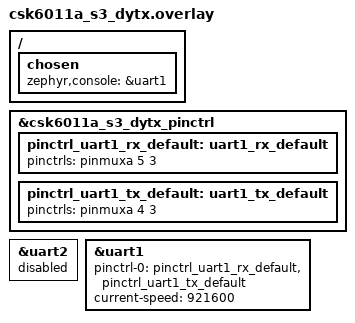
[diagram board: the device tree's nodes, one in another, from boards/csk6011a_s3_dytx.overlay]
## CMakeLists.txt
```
cmake_minimum_required(VERSION 3.20.0)

# SPDX-License-Identifier: Apache-2.0
#

set(BOARD_ROOT ${CMAKE_CURRENT_LIST_DIR})

set(ENV{XCC_USE_CLANG} "1")
set(ENV{ZEPHYR_TOOLCHAIN_VARIANT} "xcc")


find_package(Zephyr HINTS $ENV{ZEPHYR_BASE})
project(sample_sof)

target_sources(app PRIVATE
    src/main.c
  )

zephyr_ld_options(-Wl,--wrap,calloc -Wl,--wrap,malloc -Wl,--wrap,free -Wl,--wrap,printf)

zephyr_interface_library_named(sof_lib)

zephyr_library_include_directories(app PUBLIC
    ${sof_module}/src/arch/xtensa/include
    ${sof_module}/src/include
  )
```

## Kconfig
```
source "Kconfig.zephyr"

config 25M_XTAL
	bool "Use 25M XTAL instead of 24M XTAL"
	default n
	help
	  Use 25M XTAL instead of 24M XTAL
```

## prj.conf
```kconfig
CONFIG_SOF=y
CONFIG_LOG=y
CONFIG_LOG_PRINTK=y
CONFIG_LOG_MODE_MINIMAL=y

CONFIG_BUILD_OUTPUT_BIN=y
CONFIG_IPM=y
# Requires heap_info() be implemented, but no Zephyr wrapper
CONFIG_DEBUG_MEMORY_USAGE_SCAN=n

CONFIG_SCHED_DEADLINE=y
CONFIG_SCHED_CPU_MASK=y
CONFIG_SMP_BOOT_DELAY=y

#mp3 deocder
CONFIG_COMP_CODEC_ADAPTER=y
CONFIG_CADENCE_CODEC=y
CONFIG_CADENCE_CODEC_MP3_DEC=y

# cp xip
#CONFIG_CP_XIP=y
#CONFIG_CP_XIP_RUN_ADDRESS=0x68180000
#CONFIG_CP_XIP_MAX_SIZE=0x140000

# ai
#CONFIG_SOF_AI_CV=y
#CONFIG_SOF_AI_CUTLINE_RES_ADDR=0x682c0000
#CONFIG_SOF_AI_CUTLINE_RES_SIZE=0x69228
#CONFIG_SOF_AI_OCR_RES_ADDR=0x68340000
#CONFIG_SOF_AI_OCR_RES_SIZE=0x2F94A8
#CONFIG_SOF_AI_TTS_RES_ADDR=0x68640000
#CONFIG_SOF_AI_TRANS_RES_ADDR=0x68f80000

# xtensa back trace
CONFIG_XTENSA_ENABLE_BACKTRACE=y

# external libc 
# CONFIG_PRINTK=y
# CONFIG_CBPRINTF_FP_SUPPORT=y
CONFIG_STDOUT_CONSOLE=n
CONFIG_EXTERNAL_LIBC=y

# thread stack information
CONFIG_STACK_SENTINEL=y
CONFIG_INIT_STACKS=y
```

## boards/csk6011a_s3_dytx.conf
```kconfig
CONFIG_CSK6=y
CONFIG_HAVE_AGENT=n
CONFIG_FORMAT_CONVERT_HIFI3=n
CONFIG_KPB_FORCE_COPY_TYPE_NORMAL=n


# cp xip
CONFIG_CP_XIP=y
CONFIG_CP_XIP_RUN_ADDRESS=0x68180000
CONFIG_CP_XIP_MAX_SIZE=0x140000

# ai
CONFIG_SOF_AI_CV=y
CONFIG_SOF_AI_CUTLINE_RES_ADDR=0x682c0000
CONFIG_SOF_AI_CUTLINE_RES_SIZE=0x69228
CONFIG_SOF_AI_OCR_RES_ADDR=0x68340000
CONFIG_SOF_AI_OCR_RES_SIZE=0x2F94A8
CONFIG_SOF_AI_TTS_RES_ADDR=0x68640000
CONFIG_SOF_AI_TRANS_RES_ADDR=0x68f80000

CONFIG_DSP_TTS_STREAM_OUTPUT=y
```

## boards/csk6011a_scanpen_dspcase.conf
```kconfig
CONFIG_CSK6=y
CONFIG_HAVE_AGENT=n
CONFIG_FORMAT_CONVERT_HIFI3=n
CONFIG_KPB_FORCE_COPY_TYPE_NORMAL=n


# cp xip
CONFIG_CP_XIP=y
CONFIG_CP_XIP_RUN_ADDRESS=0x68460000
CONFIG_CP_XIP_MAX_SIZE=0x140000

# ai
CONFIG_SOF_AI_CV=y
CONFIG_SOF_AI_CUTLINE_RES_ADDR=0x685a0000
CONFIG_SOF_AI_CUTLINE_RES_SIZE=0x69228
CONFIG_SOF_AI_OCR_RES_ADDR=0x68620000
CONFIG_SOF_AI_OCR_RES_SIZE=0x26a0d8
CONFIG_SOF_AI_TTS_RES_ADDR=0x688a0000
CONFIG_SOF_AI_TRANS_RES_ADDR=0x68ae0000
```

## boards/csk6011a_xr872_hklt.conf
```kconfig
CONFIG_CSK6=y
CONFIG_HAVE_AGENT=n
CONFIG_FORMAT_CONVERT_HIFI3=n
CONFIG_KPB_FORCE_COPY_TYPE_NORMAL=n


# cp xip
CONFIG_CP_XIP=y
CONFIG_CP_XIP_RUN_ADDRESS=0x68100000
CONFIG_CP_XIP_MAX_SIZE=0x1b0000

# ai
CONFIG_SOF_AI_CV=y
CONFIG_SOF_AI_CUTLINE_RES_ADDR=0x682b0000
CONFIG_SOF_AI_CUTLINE_RES_SIZE=0x69228
CONFIG_SOF_AI_OCR_RES_ADDR=0x68320000
CONFIG_SOF_AI_OCR_RES_SIZE=0x2F94A8
CONFIG_AISOUND_50=n
CONFIG_SOF_AI_TTS_RES_ADDR=0x68620000
CONFIG_XTTS=y
CONFIG_SOF_AI_XTTS_FRONT_RES_ADDR=0x68620000
CONFIG_SOF_AI_XTTS_FRONT_RES_SIZE=0x327e85
CONFIG_SOF_AI_XTTS_ROLE_RES_ADDR=0x6894f000
CONFIG_SOF_AI_XTTS_ROLE_RES_SIZE=0xa02
CONFIG_SOF_AI_XTTS_REAR_RES_ADDR=0x68950000
CONFIG_SOF_AI_XTTS_REAR_RES_SIZE=0x366f90
CONFIG_SOF_AI_TRANS_RES_ADDR=0x69010000
```

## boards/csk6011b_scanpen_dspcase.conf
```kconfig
CONFIG_CSK6=y
CONFIG_HAVE_AGENT=n
CONFIG_FORMAT_CONVERT_HIFI3=n
CONFIG_KPB_FORCE_COPY_TYPE_NORMAL=n


# cp xip
CONFIG_CP_XIP=y
CONFIG_CP_XIP_RUN_ADDRESS=0x68180000
CONFIG_CP_XIP_MAX_SIZE=0x140000

# ai
CONFIG_SOF_AI_CV=y
CONFIG_SOF_AI_CUTLINE_RES_ADDR=0x682c0000
CONFIG_SOF_AI_CUTLINE_RES_SIZE=0x69228
CONFIG_SOF_AI_OCR_RES_ADDR=0x68340000
CONFIG_SOF_AI_OCR_RES_SIZE=0x26a0d8
CONFIG_SOF_AI_TTS_RES_ADDR=0x685c0000
CONFIG_SOF_AI_TRANS_RES_ADDR=0x68ae0000

CONFIG_CAPABILITY_TRANS=n
```

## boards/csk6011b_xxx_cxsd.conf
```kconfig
CONFIG_CSK6=y
CONFIG_HAVE_AGENT=n
CONFIG_FORMAT_CONVERT_HIFI3=n
CONFIG_KPB_FORCE_COPY_TYPE_NORMAL=n


# cp xip
CONFIG_CP_XIP=y
CONFIG_CP_XIP_RUN_ADDRESS=0x68100000
CONFIG_CP_XIP_MAX_SIZE=0x140000

# ai
CONFIG_SOF_AI_CV=y
CONFIG_SOF_AI_CUTLINE_RES_ADDR=0x68240000
CONFIG_SOF_AI_CUTLINE_RES_SIZE=0x69228
CONFIG_SOF_AI_OCR_RES_ADDR=0x682c0000
CONFIG_SOF_AI_OCR_RES_SIZE=0x2F94A8
CONFIG_SOF_AI_TTS_RES_ADDR=0x685c0000
CONFIG_SOF_AI_TRANS_RES_ADDR=0x68ae0000

CONFIG_SOF_AI_TRANS=n
CONFIG_DSP_TTS_STREAM_OUTPUT=y
```

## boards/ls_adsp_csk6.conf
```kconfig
CONFIG_CSK6=y
CONFIG_HAVE_AGENT=n
CONFIG_FORMAT_CONVERT_HIFI3=n
CONFIG_KPB_FORCE_COPY_TYPE_NORMAL=n

# cp xip
CONFIG_CP_XIP=y
CONFIG_CP_XIP_RUN_ADDRESS=0x68180000
CONFIG_CP_XIP_MAX_SIZE=0x140000

# ai
CONFIG_SOF_AI_CV=y
CONFIG_SOF_AI_CUTLINE_RES_ADDR=0x682c0000
CONFIG_SOF_AI_CUTLINE_RES_SIZE=0x69228
CONFIG_SOF_AI_OCR_RES_ADDR=0x68340000
CONFIG_SOF_AI_OCR_RES_SIZE=0x2F94A8
CONFIG_SOF_AI_TTS_RES_ADDR=0x68640000
CONFIG_SOF_AI_TRANS_RES_ADDR=0x68f80000
```

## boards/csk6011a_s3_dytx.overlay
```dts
/ {
	chosen {
		zephyr,console = &uart1;
	};
};

&csk6011a_s3_dytx_pinctrl{
        pinctrl_uart1_rx_default: uart1_rx_default {
			pinctrls = < &pinmuxa 5 3 >;
		};

		pinctrl_uart1_tx_default: uart1_tx_default {
			pinctrls = < &pinmuxa 4 3 >;
		};
};

&uart2 {
	status = "disabled";
};

&uart1 {
	pinctrl-0 = <&pinctrl_uart1_rx_default &pinctrl_uart1_tx_default>; 
	pinctrl-names = "default";
	current-speed = <921600>;
	status = "okay";
};
```

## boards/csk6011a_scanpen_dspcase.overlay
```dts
/ {
	chosen {
		zephyr,console = &uart1;
	};
};

&csk6011a_scanpen_dspcase_pinctrl{
        pinctrl_uart1_rx_default: uart1_rx_default {
			pinctrls = < &pinmuxa 5 3 >;
		};

		pinctrl_uart1_tx_default: uart1_tx_default {
			pinctrls = < &pinmuxa 4 3 >;
		};
};

&uart2 {
	status = "disabled";
};

&uart1 {
	pinctrl-0 = <&pinctrl_uart1_rx_default &pinctrl_uart1_tx_default>; 
	pinctrl-names = "default";
	current-speed = <921600>;
	status = "okay";
};
```

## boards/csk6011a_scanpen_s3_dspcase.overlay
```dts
/ {
	chosen {
		zephyr,console = &uart1;
	};
};

&csk6011a_scanpen_s3_dspcase_pinctrl{
        pinctrl_uart1_rx_default: uart1_rx_default {
			pinctrls = < &pinmuxa 5 3 >;
		};

		pinctrl_uart1_tx_default: uart1_tx_default {
			pinctrls = < &pinmuxa 4 3 >;
		};
};

&uart2 {
	status = "disabled";
};

&uart1 {
	pinctrl-0 = <&pinctrl_uart1_rx_default &pinctrl_uart1_tx_default>; 
	pinctrl-names = "default";
	current-speed = <921600>;
	status = "okay";
};
```

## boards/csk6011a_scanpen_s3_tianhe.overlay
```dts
/ {
	chosen {
		zephyr,console = &uart1;
	};
};

&csk6011a_scanpen_s3_tianhe_pinctrl{
        pinctrl_uart1_rx_default: uart1_rx_default {
			pinctrls = < &pinmuxa 5 3 >;
		};

		pinctrl_uart1_tx_default: uart1_tx_default {
			pinctrls = < &pinmuxa 4 3 >;
		};
};

&uart2 {
	status = "disabled";
};

&uart1 {
	pinctrl-0 = <&pinctrl_uart1_rx_default &pinctrl_uart1_tx_default>; 
	pinctrl-names = "default";
	current-speed = <921600>;
	status = "okay";
};
```

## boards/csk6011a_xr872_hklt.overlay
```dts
/ {
	chosen {
		zephyr,console = &uart1;
	};
};

&csk6011a_xr872_hklt_pinctrl{
        pinctrl_uart1_rx_default: uart1_rx_default {
			pinctrls = < &pinmuxa 5 3 >;
		};

		pinctrl_uart1_tx_default: uart1_tx_default {
			pinctrls = < &pinmuxa 4 3 >;
		};
};

&uart2 {
	status = "disabled";
};

&uart1 {
	pinctrl-0 = <&pinctrl_uart1_rx_default &pinctrl_uart1_tx_default>; 
	pinctrl-names = "default";
	current-speed = <921600>;
	status = "okay";
};
```

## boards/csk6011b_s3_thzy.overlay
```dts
/ {
	chosen {
		zephyr,console = &uart1;
	};
};

&csk6011b_s3_thzy_pinctrl{
        pinctrl_uart1_rx_default: uart1_rx_default {
			pinctrls = < &pinmuxa 5 3 >;
		};

		pinctrl_uart1_tx_default: uart1_tx_default {
			pinctrls = < &pinmuxa 4 3 >;
		};
};

&uart2 {
	status = "disabled";
};

&uart1 {
	pinctrl-0 = <&pinctrl_uart1_rx_default &pinctrl_uart1_tx_default>; 
	pinctrl-names = "default";
	current-speed = <921600>;
	status = "okay";
};
```

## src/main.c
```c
/*
 * Copyright (c) 2020 Intel Corporation.
 *
 * SPDX-License-Identifier: Apache-2.0
 */

#include <zephyr.h>

#include <logging/log.h>
LOG_MODULE_REGISTER(main, LOG_LEVEL_DBG);

/**
 * Should be included from sof/schedule/task.h
 * but triggers include chain issue
 * FIXME
 */
int sof_main(int argc, char *argv[]);

int __wrap_printf(const char * fmt, ...)
{
	static char buf[4*1024] = { 0 };
	va_list ap;

	va_start(ap, fmt);
	uint32_t n = vsnprintf(buf, sizeof(buf), fmt, ap);
	va_end(ap);

	if(n > 0) LOG_INF("[luna_err]%s", buf);

	return n;
}

void *__wrap_calloc(size_t nmemb, size_t size)
{
	return memset(k_malloc(nmemb * size), 0, nmemb * size);
}

void * __wrap_malloc(int size)
{
	return k_malloc(size);
}

void __wrap_free(void *ptr)
{
    k_free(ptr);
}

/**
 * TODO: Here comes SOF initialization
 */

void main(void)
{
	int ret;

	LOG_INF("SOF on %s", CONFIG_BOARD);

	/* sof_main is actually SOF initialization */
	ret = sof_main(0, NULL);
	if (ret) {
		LOG_ERR("SOF initialization failed");
	}

	LOG_INF("SOF initialized");
}
```
